# GD32F4xx register map
File version: 1.0
CPU: CM4 r2p1, little endian, MPU, FPU, 4 interrupt priority bits
Registers are 32-bit, read-write, reset 0x0 unless marked. A register's access mark holds for its fields unless they carry their own. Offsets are from the block's base; [hi:lo] are bit positions; {n}, {i} and the like mark numbered series.

## SYSCFG — System configuration controller
Base 0x40013800
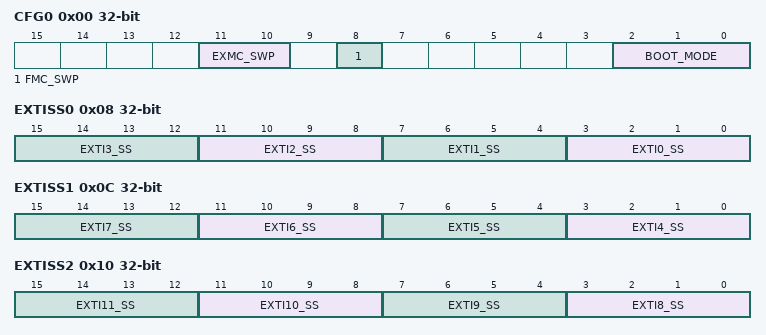
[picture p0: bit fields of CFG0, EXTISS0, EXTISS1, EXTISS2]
0x00 CFG0 — Configuration register 0
  [11:10] EXMC_SWP — EXMC memory mapping swap
  [8] FMC_SWP — FMC memory mapping swap
  [2:0] BOOT_MODE
0x04 CFG1 — Configuration register 1
  [23] ENET_PHY_SEL — Ethernet PHY selection
0x08 EXTISS0 — EXTI sources selection register 0
  [4n+3:4n] EXTI{n}_SS (n=0..3) — EXTI {n} sources selection
0x0C EXTISS1 — EXTI sources selection register 1
  [4n-13:4n-16] EXTI{n}_SS (n=4..7) — EXTI {n} sources selection
0x10 EXTISS2 — EXTI sources selection register 2
  [4n-29:4n-32] EXTI{n}_SS (n=8..11) — EXTI {n} sources selection
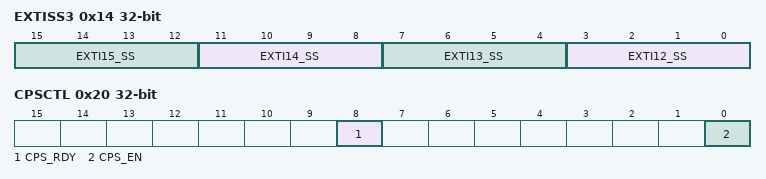
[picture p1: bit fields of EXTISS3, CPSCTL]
0x14 EXTISS3 — EXTI sources selection register 3
  [4n-45:4n-48] EXTI{n}_SS (n=12..15) — EXTI {n} sources selection
0x20 CPSCTL — I/O compensation control register
  [8] CPS_RDY — I/O compensation cell is ready or not
  [0] CPS_EN — I/O compensation cell enable

## TIMER5 — Basic-timers
Base 0x40001000
Same registers: TIMER6 0x40001400
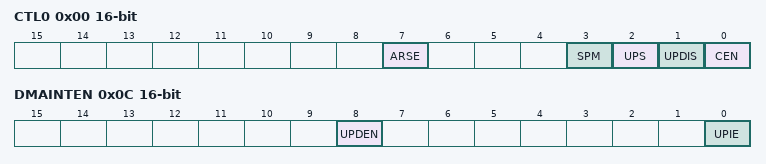
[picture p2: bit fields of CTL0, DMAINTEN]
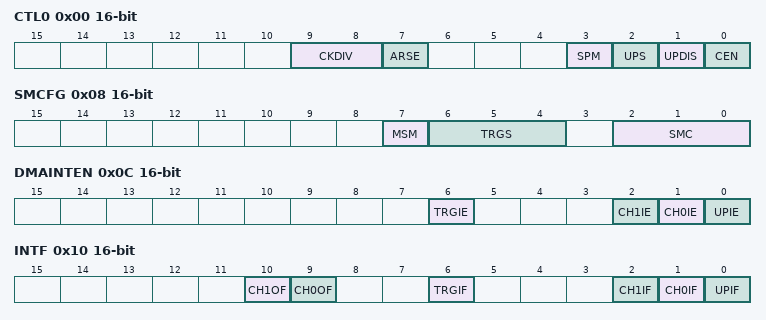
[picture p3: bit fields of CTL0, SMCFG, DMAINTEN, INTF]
0x00 CTL0 16-bit — control register 0
  [7] ARSE — Auto-reload shadow enable
  [3] SPM — Single pulse mode
  [2] UPS — Update source
  [1] UPDIS — Update disable
  [0] CEN — Counter enable
0x04 CTL1 16-bit — control register 1
  [6:4] MMC — Master mode control
0x0C DMAINTEN 16-bit — DMA/Interrupt enable register
  [8] UPDEN — Update DMA request enable
  [0] UPIE — Update interrupt enable
0x10 INTF 16-bit — Interrupt flag register
  [0] UPIF — Update interrupt flag
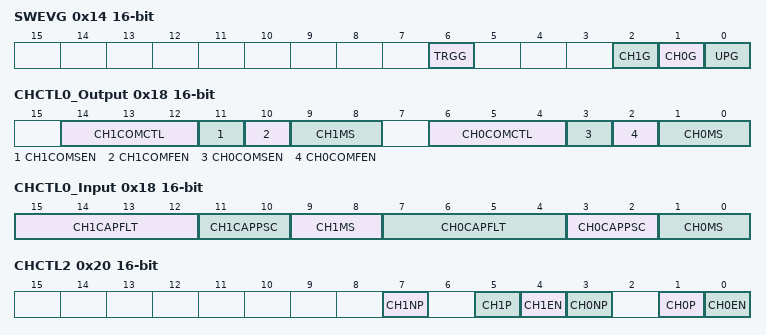
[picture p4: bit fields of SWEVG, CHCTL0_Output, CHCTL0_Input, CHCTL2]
0x14 SWEVG 16-bit wo — event generation register
  [0] UPG — Update generation
0x24 CNT 16-bit — Counter register
  [15:0] CNT — Low counter value
0x28 PSC 16-bit — Prescaler register
  [15:0] PSC — Prescaler value of the counter clock
0x2C CAR 16-bit — Counter auto reload register
  [15:0] CAR — Counter auto reload value

## TIMER8 — General-purpose-timers
Base 0x40014000
Same registers: TIMER11 0x40001800
0x00 CTL0 16-bit — control register 0
  [9:8] CKDIV — Clock division
  [7] ARSE — Auto-reload shadow enable
  [3] SPM — Single pulse mode
  [2] UPS — Update source
  [1] UPDIS — Update disable
  [0] CEN — Counter enable
0x08 SMCFG 16-bit — slave mode configuration register
  [7] MSM — Master-slave mode
  [6:4] TRGS — Trigger selection
  [2:0] SMC — Slave mode control
0x0C DMAINTEN 16-bit — DMA and interrupt enable register
  [6] TRGIE — Trigger interrupt enable
  [2] CH1IE — Channel 1 capture/compare interrupt enable
  [1] CH0IE — Channel 0 capture/compare interrupt enable
  [0] UPIE — Update interrupt enable
0x10 INTF 16-bit — interrupt flag register
  [10] CH1OF — Channel 1 over capture flag
  [9] CH0OF — Channel 0 over capture flag
  [6] TRGIF — Trigger interrupt flag
  [2] CH1IF — Channel 1 capture/compare interrupt flag
  [1] CH0IF — Channel 0 capture/compare interrupt flag
  [0] UPIF — Update interrupt flag
0x14 SWEVG 16-bit wo — event generation register
  [6] TRGG — Trigger event generation
  [2] CH1G — Channel 1 capture or compare event generation
  [1] CH0G — Channel 0 capture or compare event generation
  [0] UPG — Update generation
0x18 CHCTL0_Output 16-bit — Channel control register 0 (output mode)
  [14:12] CH1COMCTL — Channel 1 compare output control
  [11] CH1COMSEN — Channel 1 output compare shadow enable
  [10] CH1COMFEN — Channel 1 output compare fast enable
  [9:8] CH1MS — Channel 1 mode selection
  [6:4] CH0COMCTL — Channel 0 compare output control
  [3] CH0COMSEN — Channel 0 compare output shadow enable
  [2] CH0COMFEN — Channel 0 output compare fast enable
  [1:0] CH0MS — Channel 0 I/O mode selection
0x18 CHCTL0_Input 16-bit (alternate view of CHCTL0_Output) — Channel control register 0 (input mode)
  [15:12] CH1CAPFLT — Channel 1 input capture filter control
  [11:10] CH1CAPPSC — Channel 1 input capture prescaler
  [9:8] CH1MS — Channel 1 mode selection
  [7:4] CH0CAPFLT — Channel 0 input capture filter control
  [3:2] CH0CAPPSC — Channel 0 input capture prescaler
  [1:0] CH0MS — Channel 0 mode selection
0x20 CHCTL2 16-bit — Channel control register 2
  [7] CH1NP — Channel 1 complementary output polarity
  [5] CH1P — Channel 1 capture/compare function polarity
  [4] CH1EN — Channel 1 capture/compare function enable
  [3] CH0NP — Channel 0 complementary output polarity
  [1] CH0P — Channel 0 capture/compare function polarity
  [0] CH0EN — Channel 0 capture/compare function enable
0x24 CNT 16-bit — Counter register
  [15:0] CNT — current counter value
0x28 PSC 16-bit — Prescaler register
  [15:0] PSC — Prescaler value of the counter clock
0x2C CAR — Counter auto reload register
  [15:0] CARL — Counter auto reload value
0x34 CH0CV 16-bit — Channel 0 capture/compare value register
  [15:0] CH0VAL — Capture or compare value of channel0
0x38 CH1CV 16-bit — Channel 1 capture/compare value register
  [15:0] CH1VAL — Capture or compare value of channel1
0xFC CFG 16-bit — configuration register
  [1] CHVSEL — Write CHxVAL register selection
